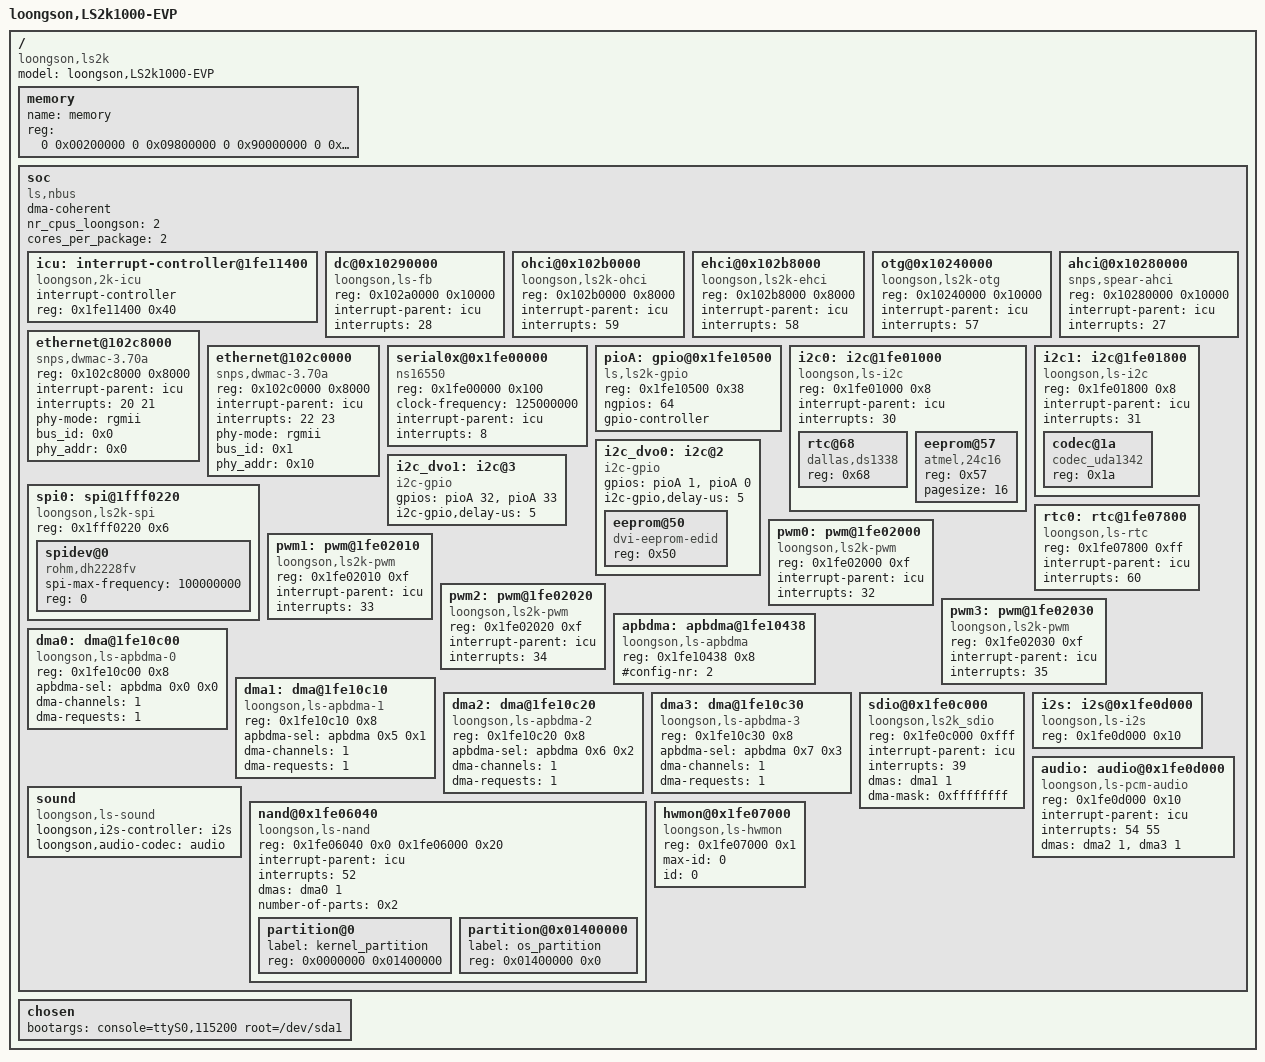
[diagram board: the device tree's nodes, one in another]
/*
 * 2K1000 Device Tree Source for LS2K1000 boards
 */

/dts-v1/;
/ {
	model = "loongson,LS2k1000-EVP";
	compatible = "loongson,ls2k";
	#address-cells = <2>;
	#size-cells = <2>;

	// Since 2K1000 support > 4GiB DIMM, use 2 cell for and address size
	memory {
		name = "memory";
		device_type = "memory";
		reg =  <0 0x00200000 0 0x09800000	// 152MiB at 2MiB
			0 0x90000000 0 0x70000000>;	// 1792MiB at 2304MiB
	};

	// all soc device use 32bit address

	soc {
		compatible = "ls,nbus", "simple-bus";
		#address-cells = <1>;
		#size-cells = <1>;
		ranges = <0x10000000 0 0x10000000 0x10000000>;
		dma-coherent;
		nr_cpus_loongson = <2>;
		cores_per_package = <2>;

		icu: interrupt-controller@1fe11400 {
			compatible = "loongson,2k-icu";
			interrupt-controller;
			#interrupt-cells = <1>;
			reg = <0x1fe11400 0x40>;
		};

		dc@0x10290000 {
			compatible = "loongson,ls-fb";
			reg = <0x102a0000 0x10000>;
			interrupt-parent = <&icu>;
			interrupts = <28>;
		};

		ohci@0x102b0000 {
			compatible = "loongson,ls2k-ohci", "usb-ohci";
			reg = <0x102b0000 0x8000>;
			interrupt-parent = <&icu>;
			interrupts = <59>;
		};

		ehci@0x102b8000 {
			compatible = "loongson,ls2k-ehci", "usb-ehci";
			reg = <0x102b8000 0x8000>;
			interrupt-parent = <&icu>;
			interrupts = <58>;
		};

		otg@0x10240000 {
			compatible = "loongson,ls2k-otg", "usb-otg";
			reg = <0x10240000 0x10000>;
			interrupt-parent = <&icu>;
			interrupts = <57>;
		};

		ahci@0x10280000 {
			compatible = "snps,spear-ahci";
			reg = <0x10280000 0x10000>;
			interrupt-parent = <&icu>;
			interrupts = <27>;
		};

		ethernet@102c8000 {
			compatible = "snps,dwmac-3.70a", "ls,ls2k-gmac";
			reg = <0x102c8000 0x8000>;
			interrupt-parent = <&icu>;
			interrupts = <20 21>;
			interrupt-names = "macirq", "eth_wake_irq";
			/*mac-address = [ 64 48 48 48 48 60 ]; [>mac 64:48:48:48:48:60 <]*/
			phy-mode = "rgmii";
            bus_id = <0x0>;
            phy_addr = <0x0>;
		};

		ethernet@102c0000 {
			compatible = "snps,dwmac-3.70a", "ls,ls2k-gmac";
			reg = <0x102c0000 0x8000>;
			interrupt-parent = <&icu>;
			interrupts = <22 23>;
			interrupt-names = "macirq", "eth_wake_irq";
			/*mac-address = [ 64 48 48 48 48 61 ]; [>mac 64:48:48:48:48:61 <]*/
			phy-mode = "rgmii";
            bus_id = <0x1>;
            phy_addr = <0x10>;
		};

		serial0x@0x1fe00000{
			device_type = "serial";
			compatible = "ns16550";
			reg = <0x1fe00000 0x100>;
			clock-frequency = <125000000>;
			interrupt-parent = <&icu>;
			interrupts = <8>;
		};

		pioA:gpio@0x1fe10500{
			compatible = "ls,ls2k-gpio", "ls,ls-gpio";
			reg = <0x1fe10500 0x38>;
			ngpios = <64>;
			gpio-controller;
			#gpio-cells = <2>;
		};

		i2c0: i2c@1fe01000{
			compatible = "loongson,ls-i2c";
			reg = <0x1fe01000 0x8>;
			interrupt-parent = <&icu>;
			interrupts = <30>;
			#address-cells = <1>;
			#size-cells = <0>;
			rtc@68{
				compatible = "dallas,ds1338";
				reg = <0x68>;
			};
			eeprom@57{
				compatible = "atmel,24c16";
				reg = <0x57>;
				pagesize = <16>;
			};
		};
		i2c1: i2c@1fe01800{
			#address-cells = <1>;
			#size-cells = <0>;

			compatible = "loongson,ls-i2c";
			reg = <0x1fe01800 0x8>;
			interrupt-parent = <&icu>;
			interrupts = <31>;
			codec@1a{
				compatible = "codec_uda1342";
				reg = <0x1a>;
			};

		};

		i2c_dvo0:i2c@2{
			compatible = "i2c-gpio";
			gpios = <&pioA 1 0 /* sda */
				 &pioA 0 0 /* scl */
				>;
			/*i2c-gpio,sda-open-drain;*/
			/*i2c-gpio,scl-open-drain;*/
			i2c-gpio,delay-us = <5>;	/* ~100 kHz */
			#address-cells = <1>;
			#size-cells = <0>;
			eeprom@50{
				compatible = "dvi-eeprom-edid";
				reg = <0x50>;
			};
		};

		i2c_dvo1:i2c@3{
			compatible = "i2c-gpio";
			gpios = <&pioA 32 0 /* sda */
				 &pioA 33 0 /* scl */
				>;
			/*i2c-gpio,sda-open-drain;*/
			/*i2c-gpio,scl-open-drain;*/
			i2c-gpio,delay-us = <5>;	/* ~100 kHz */
		};

		spi0: spi@1fff0220{
			compatible = "loongson,ls2k-spi";
			#address-cells = <1>;
			#size-cells = <0>;
			reg = <0x1fff0220 0x6>;
			spidev@0{
				compatible = "rohm,dh2228fv";
				spi-max-frequency = <100000000>;
				reg = <0>;
			};
		};
		rtc0: rtc@1fe07800{
			compatible = "loongson,ls-rtc";
			reg = <0x1fe07800 0xff>;
			interrupt-parent = <&icu>;
			interrupts = <60>;
		};

		/* CAN controller nodes:
		 * If you want to use the "can" function,enable the "can"
		 * controller by configure general configuration register 0.
		 */
		/*can0: can@1fe00c00{
			compatible = "nxp,sja1000";
			reg = <0x1fe00c00 0xff>;
			interrupt-parent = <&icu>;
			interrupts = <24>;
		};
		can1: can@1fe00d00{
			compatible = "nxp,sja1000";
			reg = <0x1fe00d00 0xff>;
			interrupt-parent = <&icu>;
			interrupts = <25>;
		};*/

		pwm0: pwm@1fe02000{
		    compatible = "loongson,ls2k-pwm";
		    reg = <0x1fe02000 0xf>;
		    interrupt-parent = <&icu>;
		    interrupts = <32>;
		};
		pwm1: pwm@1fe02010{
			compatible = "loongson,ls2k-pwm";
			reg = <0x1fe02010 0xf>;
			interrupt-parent = <&icu>;
			interrupts = <33>;
		};
		pwm2: pwm@1fe02020{
			compatible = "loongson,ls2k-pwm";
			reg = <0x1fe02020 0xf>;
			interrupt-parent = <&icu>;
			interrupts = <34>;
		};
		pwm3: pwm@1fe02030{
			compatible = "loongson,ls2k-pwm";
			reg = <0x1fe02030 0xf>;
			interrupt-parent = <&icu>;
			interrupts = <35>;
		};

		/* APB DMA controller nodes:
		 * apbdma node specify the commom property for dma node.
		 * the #config-nr must be 2,Used to provide APB sel region
		 * and APB DMA controler information.
		 */
		apbdma: apbdma@1fe10438{
			compatible = "loongson,ls-apbdma";
			reg = <0x1fe10438 0x8>;
			#config-nr = <2>;
		};
		/* DMA node should specify the apbdma-sel property using a
		 * phandle to the controller followed by number of APB sel
		 * region(max 9) and number of APB DMA controller(max 4).
		*/
		dma0: dma@1fe10c00 {
			compatible = "loongson,ls-apbdma-0";
			reg = <0x1fe10c00 0x8>;
			apbdma-sel = <&apbdma 0x0 0x0>;
			#dma-cells = <1>;
			dma-channels = <1>;
			dma-requests = <1>;
		};
		dma1: dma@1fe10c10 {
			compatible = "loongson,ls-apbdma-1";
			reg = <0x1fe10c10 0x8>;
			apbdma-sel = <&apbdma 0x5 0x1>;
			#dma-cells = <1>;
			dma-channels = <1>;
			dma-requests = <1>;
		};
		dma2: dma@1fe10c20 {
			compatible = "loongson,ls-apbdma-2";
			reg = <0x1fe10c20 0x8>;
			apbdma-sel = <&apbdma 0x6 0x2>;
			#dma-cells = <1>;
			dma-channels = <1>;
			dma-requests = <1>;
		};
		dma3: dma@1fe10c30 {
			compatible = "loongson,ls-apbdma-3";
			reg = <0x1fe10c30 0x8>;
			apbdma-sel = <&apbdma 0x7 0x3>;
			#dma-cells = <1>;
			dma-channels = <1>;
			dma-requests = <1>;
		};
		/*
		dma4: dma@1fe10c40 {
			compatible = "loongson,ls-apbdma-4";
			apbdma-sel = <&apbdma 0x0 0x0>;
			reg = <0x1fe10c40 0x8>;
			#dma-cells = <1>;
			dma-channels = <1>;
			dma-requests = <1>;
		};
		*/
		sdio@0x1fe0c000 {
			#address-cells = <1>;
			#size-cells = <1>;

			compatible = "loongson,ls2k_sdio";
			reg = <0x1fe0c000 0xfff>;
			interrupt-parent = <&icu>;
			interrupts = <39>;
			interrupt-names = "ls2k_mci_irq";

			dmas = <&dma1 1>;
			dma-names = "sdio_rw";
			dma-mask = <0xffffffff>;
		};
		i2s: i2s@0x1fe0d000 {
			compatible = "loongson,ls-i2s";
			reg = <0x1fe0d000 0x10>;
		};
		audio: audio@0x1fe0d000 {
			compatible = "loongson,ls-pcm-audio";
			reg = <0x1fe0d000 0x10>;
			interrupt-parent = <&icu>;
			interrupts = <54 55>;
			interrupt-names = "i2s_irq0", "i2s_irq1";

			dmas = <&dma2 1
			        &dma3 1>;
			dma-names = "i2s_play", "i2s_record";
		};
		sound {
			compatible = "loongson,ls-sound";
			loongson,i2s-controller = <&i2s>;
			loongson,audio-codec = <&audio>;
		};
		nand@0x1fe06040{
			#address-cells = <1>;
			#size-cells = <1>;
			compatible = "loongson,ls-nand";
			reg = <0x1fe06040 0x0
				0x1fe06000 0x20>;
			interrupt-parent = <&icu>;
			interrupts = <52>;
			interrupt-names = "nand_irq";

			dmas = <&dma0 1>;
			dma-names = "nand_rw";

			number-of-parts = <0x2>;

			partition@0 {
				label = "kernel_partition";
				reg = <0x0000000 0x01400000>;
			};

			partition@0x01400000 {
				label = "os_partition";
				reg = <0x01400000 0x0>;
			};
		};
		hwmon@0x1fe07000{
			#address-cells = <1>;
			#size-cells = <1>;

			compatible = "loongson,ls-hwmon";
			reg = <0x1fe07000 0x1>;
			max-id = <0>;
			id = <0>;
		};
	};

	chosen {
		bootargs = "console=ttyS0,115200 root=/dev/sda1";
	};
};
